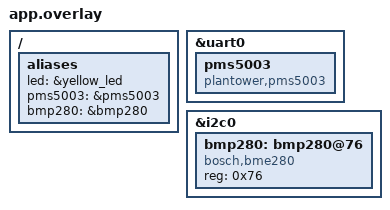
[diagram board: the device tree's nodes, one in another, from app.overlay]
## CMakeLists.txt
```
cmake_minimum_required(VERSION 3.20.0)

find_package(Zephyr REQUIRED)

project(app LANGUAGES C)

target_sources(app PRIVATE src/main.c src/bmp280.c src/pms5003.c src/led.c)
```

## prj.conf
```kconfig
CONFIG_LOG=n
CONFIG_LOG_DEFAULT_LEVEL=3

CONFIG_GPIO=y
CONFIG_LED=y
CONFIG_SENSOR=y
CONFIG_WIFI=y

CONFIG_PM_DEVICE=y

CONFIG_NETWORKING=y
CONFIG_NET_MGMT=y
CONFIG_NET_MGMT_EVENT=y
CONFIG_NET_L2_WIFI_MGMT=y

CONFIG_NET_IPV4=y
CONFIG_NET_DHCPV4=y
CONFIG_NET_SOCKETS=y
CONFIG_NET_TCP=y
CONFIG_NET_UDP=y
CONFIG_HTTP_CLIENT=y

CONFIG_NET_HOSTNAME_ENABLE=y
```

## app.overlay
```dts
#include <zephyr/dt-bindings/pinctrl/esp32c6-pinctrl.h>

/ {
    aliases {
        led = &yellow_led;
        pms5003 = &pms5003;
        bmp280 = &bmp280;
    };
};

&uart0 {
    status = "okay";

    pms5003: pms5003 {
        status = "okay";
        compatible = "plantower,pms5003";
   };
};

&i2c0 {
    status = "okay";

    bmp280: bmp280@76 {
        status = "okay";
        compatible = "bosch,bme280";
        reg = <0x76>;
    };
};
```

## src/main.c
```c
#include <zephyr/kernel.h>
#include <zephyr/drivers/led.h>
#include <zephyr/drivers/sensor.h>
#include <zephyr/logging/log.h>

#include "reading.h"
#include "state.h"

LOG_MODULE_REGISTER(main, CONFIG_LOG_DEFAULT_LEVEL);

// App

enum app_state app_state = STATE_CONNECT;

// Devices

static const struct led_dt_spec led = LED_DT_SPEC_GET(DT_ALIAS(led));
static const struct device *bmp280 = DEVICE_DT_GET(DT_ALIAS(bmp280));
static const struct device *pms5003 = DEVICE_DT_GET(DT_ALIAS(pms5003));

// Queues

K_MSGQ_DEFINE(msgq_readings, sizeof(struct reading), 16, 1);

// BMP280 thread

void bmp280_handler(void *arg1, void *arg2, void *arg3);
K_THREAD_DEFINE(bmp280_tid, 1024, bmp280_handler, &msgq_readings, NULL, NULL, 5, 0, 5000);

// PMS5003 thread

void pms5003_handler(void *arg1, void *arg2, void *arg3);
K_THREAD_DEFINE(pms5003_tid, 1024, pms5003_handler, &msgq_readings, NULL, NULL, 5, 0, 5000);

// LED thread

// void led_handler(void *arg1, void *arg2, void *arg3);
// K_THREAD_DEFINE(led_tid, 512, led_handler, &app_state, NULL, NULL, 10, 0, 0);

// Main

int main(void) {
    // Initialize devices

    if (!led_is_ready_dt(&led))
        return -1;

    if (!device_is_ready(pms5003))
        return -1;

    if (!device_is_ready(bmp280))
        return -1;

    int ret;
    struct reading reading;

    while (1) {
        ret = k_msgq_get(&msgq_readings, &reading, K_FOREVER);

        if (ret)
            continue;

        switch (reading.channel) {
            case SENSOR_CHAN_AMBIENT_TEMP:
                printk("temp:%d.%d\n", reading.value.val1, reading.value.val2 / 10000);
                break;
            case SENSOR_CHAN_PRESS:
                printk("press:%d%d\n", reading.value.val1, reading.value.val2 / 100000);
                break;
            case SENSOR_CHAN_PM_1_0_CF:
                printk("pm1.0:%d\n", reading.value.val1);
                break;
            case SENSOR_CHAN_PM_2_5_CF:
                printk("pm2.5:%d\n", reading.value.val1);
                break;
            case SENSOR_CHAN_PM_10_CF:
                printk("pm10:%d\n", reading.value.val1);
                break;
            default:
                break;
        }
    }

    return 0;
}
```

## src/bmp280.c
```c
#include <zephyr/kernel.h>
#include <zephyr/drivers/sensor.h>

#include "reading.h"

#define BMP280_DELAY K_SECONDS(60)

static const struct device *bmp280 = DEVICE_DT_GET(DT_ALIAS(bmp280));

void bmp280_handler(struct k_msgq *msgq, void *arg2, void *arg3) {
    int ret;
    struct reading reading;

    while (1) {
        ret = sensor_sample_fetch(bmp280);

        if (ret) {
            k_sleep(BMP280_DELAY);
            continue;
        }

        reading.channel = SENSOR_CHAN_AMBIENT_TEMP;
        sensor_channel_get(bmp280, SENSOR_CHAN_AMBIENT_TEMP, &(reading.value));
        k_msgq_put(msgq, &reading, K_FOREVER);

        reading.channel = SENSOR_CHAN_PRESS;
        sensor_channel_get(bmp280, SENSOR_CHAN_PRESS, &(reading.value));
        k_msgq_put(msgq, &reading, K_FOREVER);

        k_sleep(BMP280_DELAY);
    }
}
```

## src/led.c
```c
#include <zephyr/kernel.h>
#include <zephyr/drivers/led.h>

#include "state.h"

static const struct led_dt_spec led = LED_DT_SPEC_GET(DT_ALIAS(led));

void led_handler(enum app_state *state, void *arg2, void *arg3) {
    while (1) {
        switch (*state) {
            case STATE_CONNECT:
                led_on_dt(&led);
                k_msleep(500);
                led_off_dt(&led);
                k_msleep(500);
                break;
            case STATE_RUN:
                led_on_dt(&led);
                k_msleep(1000);
                break;
        }
    }
}
```

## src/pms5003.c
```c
#include <zephyr/kernel.h>
#include <zephyr/drivers/sensor.h>
#include <zephyr/pm/device.h>

#include "reading.h"

#define PMS5003_DELAY K_SECONDS(60 * 4 + 30)

static const struct device *pms5003 = DEVICE_DT_GET(DT_ALIAS(pms5003));

void pms5003_handler(struct k_msgq *msgq, void *arg2, void *arg3) {
    int ret;
    struct reading reading;

    while (1) {
        pm_device_action_run(pms5003, PM_DEVICE_ACTION_RESUME);

        k_sleep(K_SECONDS(30));

        ret = sensor_sample_fetch(pms5003);

        if (ret) {
            pm_device_action_run(pms5003, PM_DEVICE_ACTION_SUSPEND);
            k_sleep(PMS5003_DELAY);
            continue;
        }

        pm_device_action_run(pms5003, PM_DEVICE_ACTION_SUSPEND);

        reading.channel = SENSOR_CHAN_PM_1_0_CF;
        sensor_channel_get(pms5003, SENSOR_CHAN_PM_1_0_CF, &(reading.value));
        k_msgq_put(msgq, &reading, K_FOREVER);

        reading.channel = SENSOR_CHAN_PM_2_5_CF;
        sensor_channel_get(pms5003, SENSOR_CHAN_PM_2_5_CF, &(reading.value));
        k_msgq_put(msgq, &reading, K_FOREVER);

        reading.channel = SENSOR_CHAN_PM_10_CF;
        sensor_channel_get(pms5003, SENSOR_CHAN_PM_10_CF, &(reading.value));
        k_msgq_put(msgq, &reading, K_FOREVER);

        k_sleep(PMS5003_DELAY);
    }
}
```

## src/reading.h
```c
#ifndef READING_H
#define READING_H

#include <zephyr/drivers/sensor.h>

struct reading {
    enum sensor_channel channel;
    struct sensor_value value;
};

#endif // READING_H
```

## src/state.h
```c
#ifndef STATE_H_
#define STATE_H_

enum app_state { STATE_CONNECT, STATE_RUN };
enum app_event { EVENT_CONNECTED, EVENT_DISCONNECTED };

#endif // STATE_H_
```
